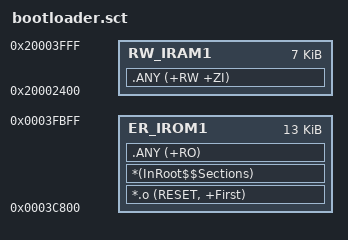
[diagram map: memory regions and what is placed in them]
; *************************************************************
; *** Scatter-Loading Description File generated by uVision ***
; *************************************************************

LR_IROM1 0x0003C800 0x00003400  {    ; load region size_region
  ER_IROM1 0x0003C800 0x00003400  {  ; load address = execution address
   *.o (RESET, +First)
   *(InRoot$$Sections)
   .ANY (+RO)
  }
  RW_IRAM1 0x20002400 0x00001C00  {  ; RW data
   .ANY (+RW +ZI)
  }
}

